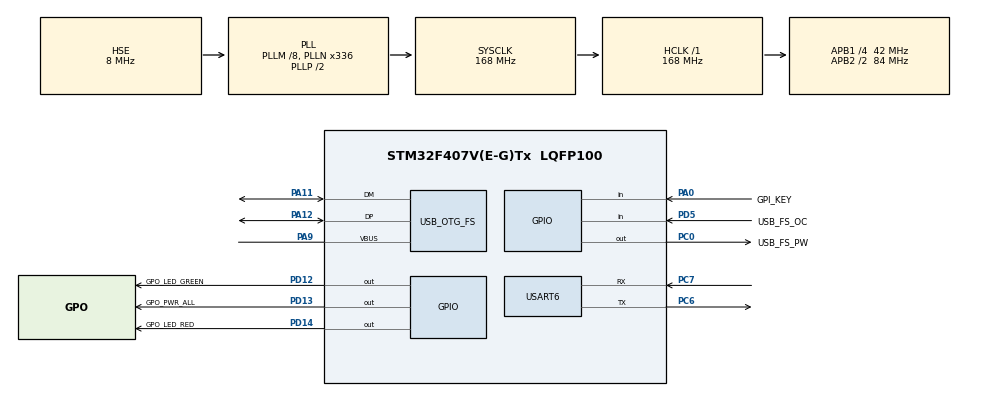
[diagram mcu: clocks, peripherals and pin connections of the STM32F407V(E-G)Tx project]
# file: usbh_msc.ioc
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FREERTOS.Tasks01=defaultTask,0,128,StartDefaultTask,Default,NULL
Mcu.Family=STM32F4
Mcu.Name=STM32F407V(E-G)Tx
Mcu.Package=LQFP100
NVIC.OTG_FS_IRQn=true\:5\:0\:false\:false\:true\:true\:false
NVIC.PriorityGroup=NVIC_PRIORITYGROUP_4
NVIC.TIM7_IRQn=true\:0\:0\:false\:false\:true\:false\:false
NVIC.TimeBase=TIM7_IRQn
NVIC.TimeBaseIP=TIM7
PA0-WKUP.GPIO_Label=GPI_KEY
PA0-WKUP.Signal=GPIO_Input
PA11.Mode=Host_Only
PA11.Signal=USB_OTG_FS_DM
PA12.Mode=Host_Only
PA12.Signal=USB_OTG_FS_DP
PA13.Mode=Serial_Wire
PA13.Signal=SYS_JTMS-SWDIO
PA14.Mode=Serial_Wire
PA14.Signal=SYS_JTCK-SWCLK
PA9.Mode=Activate_VBUS
PA9.Signal=USB_OTG_FS_VBUS
PC0.GPIO_Label=USB_FS_PW
PC0.Signal=GPIO_Output
PC6.Mode=Asynchronous
PC6.Signal=USART6_TX
PC7.Mode=Asynchronous
PC7.Signal=USART6_RX
PD12.GPIO_Label=GPO_LED_GREEN
PD12.Signal=GPIO_Output
PD13.GPIO_Label=GPO_PWR_ALL
PD13.Signal=GPIO_Output
PD14.GPIO_Label=GPO_LED_RED
PD14.Signal=GPIO_Output
PD5.GPIO_Label=USB_FS_OC
PD5.Signal=GPIO_Input
PH0-OSC_IN.Mode=HSE-External-Oscillator
PH0-OSC_IN.Signal=RCC_OSC_IN
PH1-OSC_OUT.Mode=HSE-External-Oscillator
PH1-OSC_OUT.Signal=RCC_OSC_OUT
ProjectManager.HeapSize=0x2000
ProjectManager.StackSize=0x4000
ProjectManager.TargetToolchain=MDK-ARM V5
RCC.48MHZClocksFreq_Value=48000000
RCC.AHBFreq_Value=168000000
RCC.APB1CLKDivider=RCC_HCLK_DIV4
RCC.APB1Freq_Value=42000000
RCC.APB1TimFreq_Value=84000000
RCC.APB2CLKDivider=RCC_HCLK_DIV2
RCC.APB2Freq_Value=84000000
RCC.APB2TimFreq_Value=168000000
RCC.CortexFreq_Value=168000000
RCC.HCLKFreq_Value=168000000
RCC.HSE_VALUE=8000000
RCC.HSI_VALUE=16000000
RCC.LSE_VALUE=32768
RCC.PLLM=8
RCC.PLLN=336
RCC.PLLQ=7
RCC.SYSCLKFreq_VALUE=168000000
RCC.SYSCLKSource=RCC_SYSCLKSOURCE_PLLCLK
RCC.VCOOutputFreq_Value=336000000
USART6.VirtualMode=VM_ASYNC
USB_HOST.USBH_HandleTypeDef-MSC_FS=hUsbHostFS
USB_HOST.VirtualModeFS=Msc
USB_OTG_FS.VirtualMode=Host_Only
USB_OTG_FS.phy_itface=HCD_PHY_EMBEDDED
VP_FATFS_VS_USB.Mode=USB
VP_FREERTOS_VS_ENABLE.Mode=Enabled
VP_SYS_VS_tim7.Mode=TIM7
VP_USB_HOST_VS_USB_HOST_MSC_FS.Mode=MSC_FS
board=usbh_msc

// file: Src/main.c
/**
  ******************************************************************************
  * File Name          : main.c
  * Description        : Main program body
  ******************************************************************************
  * This notice applies to any and all portions of this file
  * that are not between comment pairs USER CODE BEGIN and
  * USER CODE END. Other portions of this file, whether
  * inserted by the user or by software development tools
  * are owned by their respective copyright owners.
  *
  * Copyright (c) 2018 STMicroelectronics International N.V.
  * All rights reserved.
  *
  * Redistribution and use in source and binary forms, with or without
  * modification, are permitted, provided that the following conditions are met:
  *
  * 1. Redistribution of source code must retain the above copyright notice,
  *    this list of conditions and the following disclaimer.
  * 2. Redistributions in binary form must reproduce the above copyright notice,
  *    this list of conditions and the following disclaimer in the documentation
  *    and/or other materials provided with the distribution.
  * 3. Neither the name of STMicroelectronics nor the names of other
  *    contributors to this software may be used to endorse or promote products
  *    derived from this software without specific written permission.
  * 4. This software, including modifications and/or derivative works of this
  *    software, must execute solely and exclusively on microcontroller or
  *    microprocessor devices manufactured by or for STMicroelectronics.
  * 5. Redistribution and use of this software other than as permitted under
  *    this license is void and will automatically terminate your rights under
  *    this license.
  *
  * THIS SOFTWARE IS PROVIDED BY STMICROELECTRONICS AND CONTRIBUTORS "AS IS"
  * AND ANY EXPRESS, IMPLIED OR STATUTORY WARRANTIES, INCLUDING, BUT NOT
  * LIMITED TO, THE IMPLIED WARRANTIES OF MERCHANTABILITY, FITNESS FOR A
  * PARTICULAR PURPOSE AND NON-INFRINGEMENT OF THIRD PARTY INTELLECTUAL PROPERTY
  * RIGHTS ARE DISCLAIMED TO THE FULLEST EXTENT PERMITTED BY LAW. IN NO EVENT
  * SHALL STMICROELECTRONICS OR CONTRIBUTORS BE LIABLE FOR ANY DIRECT, INDIRECT,
  * INCIDENTAL, SPECIAL, EXEMPLARY, OR CONSEQUENTIAL DAMAGES (INCLUDING, BUT NOT
  * LIMITED TO, PROCUREMENT OF SUBSTITUTE GOODS OR SERVICES; LOSS OF USE, DATA,
  * OR PROFITS; OR BUSINESS INTERRUPTION) HOWEVER CAUSED AND ON ANY THEORY OF
  * LIABILITY, WHETHER IN CONTRACT, STRICT LIABILITY, OR TORT (INCLUDING
  * NEGLIGENCE OR OTHERWISE) ARISING IN ANY WAY OUT OF THE USE OF THIS SOFTWARE,
  * EVEN IF ADVISED OF THE POSSIBILITY OF SUCH DAMAGE.
  *
  ******************************************************************************
  */

#include "main.h"
#include "stm32f4xx_hal.h"
#include "cmsis_os.h"
#include "fatfs.h"
#include "usart.h"
#include "usb_host.h"
#include "gpio.h"

/* USER CODE BEGIN PV */
/* Private variables ---------------------------------------------------------*/

/* USER CODE END PV */

void SystemClock_Config(void);
void MX_FREERTOS_Init(void);

/* USER CODE BEGIN PFP */
/* Private function prototypes -----------------------------------------------*/

/* USER CODE END PFP */

int main(void)
{

  /* MCU Configuration----------------------------------------------------------*/

  /* Reset of all peripherals, Initializes the Flash interface and the Systick. */
  HAL_Init();

  /* Configure the system clock */
  SystemClock_Config();

  /* Initialize all configured peripherals */
  MX_GPIO_Init();
  MX_USART6_UART_Init();

  /* Call init function for freertos objects (in freertos.c) */
  MX_FREERTOS_Init();

  /* Start scheduler */
  osKernelStart();

  /* We should never get here as control is now taken by the scheduler */

  /* Infinite loop */
  while (1)
  {

  }

}

/** System Clock Configuration
*/
void SystemClock_Config(void)
{

  RCC_OscInitTypeDef RCC_OscInitStruct;
  RCC_ClkInitTypeDef RCC_ClkInitStruct;

    /**Configure the main internal regulator output voltage
    */
  __HAL_RCC_PWR_CLK_ENABLE();

  __HAL_PWR_VOLTAGESCALING_CONFIG(PWR_REGULATOR_VOLTAGE_SCALE1);

    /**Initializes the CPU, AHB and APB busses clocks
    */
  RCC_OscInitStruct.OscillatorType = RCC_OSCILLATORTYPE_HSE;
  RCC_OscInitStruct.HSEState = RCC_HSE_ON;
  RCC_OscInitStruct.PLL.PLLState = RCC_PLL_ON;
  RCC_OscInitStruct.PLL.PLLSource = RCC_PLLSOURCE_HSE;
  RCC_OscInitStruct.PLL.PLLM = 8;
  RCC_OscInitStruct.PLL.PLLN = 336;
  RCC_OscInitStruct.PLL.PLLP = RCC_PLLP_DIV2;
  RCC_OscInitStruct.PLL.PLLQ = 7;
  if (HAL_RCC_OscConfig(&RCC_OscInitStruct) != HAL_OK)
  {
    _Error_Handler(__FILE__, __LINE__);
  }

    /**Initializes the CPU, AHB and APB busses clocks
    */
  RCC_ClkInitStruct.ClockType = RCC_CLOCKTYPE_HCLK|RCC_CLOCKTYPE_SYSCLK
                              |RCC_CLOCKTYPE_PCLK1|RCC_CLOCKTYPE_PCLK2;
  RCC_ClkInitStruct.SYSCLKSource = RCC_SYSCLKSOURCE_PLLCLK;
  RCC_ClkInitStruct.AHBCLKDivider = RCC_SYSCLK_DIV1;
  RCC_ClkInitStruct.APB1CLKDivider = RCC_HCLK_DIV4;
  RCC_ClkInitStruct.APB2CLKDivider = RCC_HCLK_DIV2;

  if (HAL_RCC_ClockConfig(&RCC_ClkInitStruct, FLASH_LATENCY_5) != HAL_OK)
  {
    _Error_Handler(__FILE__, __LINE__);
  }

    /**Configure the Systick interrupt time
    */
  HAL_SYSTICK_Config(HAL_RCC_GetHCLKFreq()/1000);

    /**Configure the Systick
    */
  HAL_SYSTICK_CLKSourceConfig(SYSTICK_CLKSOURCE_HCLK);

  /* SysTick_IRQn interrupt configuration */
  HAL_NVIC_SetPriority(SysTick_IRQn, 15, 0);
}

void HAL_TIM_PeriodElapsedCallback(TIM_HandleTypeDef *htim)
{
  if (htim->Instance == TIM7) {
    HAL_IncTick();
  }
}

void _Error_Handler(char * file, int line)
{
  while(1)
  {
  }
}

/************************ (C) COPYRIGHT STMicroelectronics *****END OF FILE****/

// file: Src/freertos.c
/**
  ******************************************************************************
  * File Name          : freertos.c
  * Description        : Code for freertos applications
  ******************************************************************************
  * This notice applies to any and all portions of this file
  * that are not between comment pairs USER CODE BEGIN and
  * USER CODE END. Other portions of this file, whether
  * inserted by the user or by software development tools
  * are owned by their respective copyright owners.
  *
  * Copyright (c) 2018 STMicroelectronics International N.V.
  * All rights reserved.
  *
  * Redistribution and use in source and binary forms, with or without
  * modification, are permitted, provided that the following conditions are met:
  *
  * 1. Redistribution of source code must retain the above copyright notice,
  *    this list of conditions and the following disclaimer.
  * 2. Redistributions in binary form must reproduce the above copyright notice,
  *    this list of conditions and the following disclaimer in the documentation
  *    and/or other materials provided with the distribution.
  * 3. Neither the name of STMicroelectronics nor the names of other
  *    contributors to this software may be used to endorse or promote products
  *    derived from this software without specific written permission.
  * 4. This software, including modifications and/or derivative works of this
  *    software, must execute solely and exclusively on microcontroller or
  *    microprocessor devices manufactured by or for STMicroelectronics.
  * 5. Redistribution and use of this software other than as permitted under
  *    this license is void and will automatically terminate your rights under
  *    this license.
  *
  * THIS SOFTWARE IS PROVIDED BY STMICROELECTRONICS AND CONTRIBUTORS "AS IS"
  * AND ANY EXPRESS, IMPLIED OR STATUTORY WARRANTIES, INCLUDING, BUT NOT
  * LIMITED TO, THE IMPLIED WARRANTIES OF MERCHANTABILITY, FITNESS FOR A
  * PARTICULAR PURPOSE AND NON-INFRINGEMENT OF THIRD PARTY INTELLECTUAL PROPERTY
  * RIGHTS ARE DISCLAIMED TO THE FULLEST EXTENT PERMITTED BY LAW. IN NO EVENT
  * SHALL STMICROELECTRONICS OR CONTRIBUTORS BE LIABLE FOR ANY DIRECT, INDIRECT,
  * INCIDENTAL, SPECIAL, EXEMPLARY, OR CONSEQUENTIAL DAMAGES (INCLUDING, BUT NOT
  * LIMITED TO, PROCUREMENT OF SUBSTITUTE GOODS OR SERVICES; LOSS OF USE, DATA,
  * OR PROFITS; OR BUSINESS INTERRUPTION) HOWEVER CAUSED AND ON ANY THEORY OF
  * LIABILITY, WHETHER IN CONTRACT, STRICT LIABILITY, OR TORT (INCLUDING
  * NEGLIGENCE OR OTHERWISE) ARISING IN ANY WAY OUT OF THE USE OF THIS SOFTWARE,
  * EVEN IF ADVISED OF THE POSSIBILITY OF SUCH DAMAGE.
  *
  ******************************************************************************
  */

#include "FreeRTOS.h"
#include "task.h"
#include "cmsis_os.h"

/* USER CODE BEGIN Includes */

#include "task_start.h"
#include "task_usb.h"

/* USER CODE END Includes */

osThreadId defaultTaskHandle;

/* USER CODE BEGIN Variables */

osThreadId g_usb_handle;

/* USER CODE END Variables */

void StartDefaultTask(void const * argument);

extern void MX_USB_HOST_Init(void);
extern void MX_FATFS_Init(void);
void MX_FREERTOS_Init(void); /* (MISRA C 2004 rule 8.1) */

/* Hook prototypes */

/* Init FreeRTOS */

void MX_FREERTOS_Init(void) {
  /* USER CODE BEGIN Init */

	task_freertos_init();

  /* USER CODE END Init */

  /* USER CODE BEGIN RTOS_SEMAPHORES */

	task_start_creat_sem();
	task_usb_creat_sem();

  /* USER CODE END RTOS_SEMAPHORES */

  /* Create the thread(s) */
  /* definition and creation of defaultTask */
  osThreadDef(defaultTask, StartDefaultTask, osPriorityNormal, 0, 128);
  defaultTaskHandle = osThreadCreate(osThread(defaultTask), NULL);

  /* USER CODE BEGIN RTOS_THREADS */

	osThreadDef(Task_USB, task_usb, osPriorityNormal, 0, 256);
	g_usb_handle = osThreadCreate(osThread(Task_USB), NULL);

  /* USER CODE END RTOS_THREADS */

}

/* StartDefaultTask function */
void StartDefaultTask(void const * argument)
{
  /* init code for USB_HOST */
  MX_USB_HOST_Init();

  /* init code for FATFS */
  MX_FATFS_Init();

  /* USER CODE BEGIN StartDefaultTask */
  /* Infinite loop */

	for(;;){
		task_start(argument);
	}

  /* USER CODE END StartDefaultTask */
}

/************************ (C) COPYRIGHT STMicroelectronics *****END OF FILE****/
